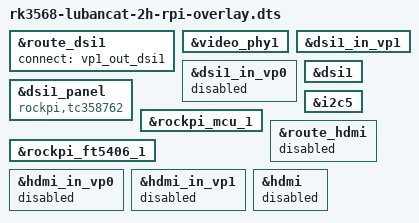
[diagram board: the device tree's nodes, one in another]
/dts-v1/;
/plugin/;

#include <dt-bindings/gpio/gpio.h>
#include <dt-bindings/pinctrl/rockchip.h>
#include <dt-bindings/display/drm_mipi_dsi.h>
#include <dt-bindings/interrupt-controller/irq.h>

/ {

	fragment@0 {
		target = <&route_dsi1>;

		__overlay__ {
			status = "okay";
			connect = <&vp1_out_dsi1>;
		};
	};

	fragment@1 {
		target = <&video_phy1>;

		__overlay__ {
			status = "okay";
		};
	};

	fragment@2 {
		target = <&dsi1_in_vp1>;

		__overlay__ {
			status = "okay";
		};
	};

	fragment@3 {
		target = <&dsi1_in_vp0>;

		__overlay__ {
			status = "disabled";
		};
	};

	fragment@4 {
		target = <&dsi1>;

		__overlay__ {
			status = "okay";
		};
	};

	fragment@5 {
		target = <&dsi1_panel>;

		__overlay__ {
			compatible = "rockpi,tc358762";
			status = "okay";
		};
	};

	fragment@6 {
		target = <&i2c5>;

		__overlay__ {
			status = "okay";
		};
	};

	fragment@7 {
		target = <&rockpi_mcu_1>;

		__overlay__ {
			status = "okay";
		};
	};

	fragment@8 {
		target = <&rockpi_ft5406_1>;

		__overlay__ {
			status = "okay";
		};
	};
		
	fragment@9 {
		target = <&route_hdmi>;

		__overlay__ {
			status = "disabled";
		};
	};

	fragment@10 {
		target = <&hdmi_in_vp0>;

		__overlay__ {
			status = "disabled";
		};
	};

	fragment@11 {
		target = <&hdmi_in_vp1>;

		__overlay__ {
			status = "disabled";
		};
	};

	fragment@12 {
		target = <&hdmi>;

		__overlay__ {
			status = "disabled";
		};
	};
};
